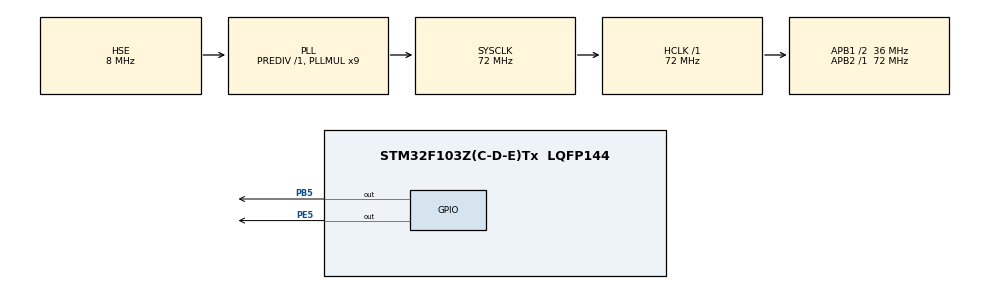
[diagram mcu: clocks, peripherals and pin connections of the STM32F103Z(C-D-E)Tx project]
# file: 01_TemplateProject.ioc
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Mcu.Family=STM32F1
Mcu.Name=STM32F103Z(C-D-E)Tx
Mcu.Package=LQFP144
NVIC.PriorityGroup=NVIC_PRIORITYGROUP_4
OSC_IN.Mode=HSE-External-Oscillator
OSC_IN.Signal=RCC_OSC_IN
OSC_OUT.Mode=HSE-External-Oscillator
OSC_OUT.Signal=RCC_OSC_OUT
PB5.GPIO_PuPd=GPIO_PULLUP
PB5.GPIO_Speed=GPIO_SPEED_FREQ_HIGH
PB5.PinState=GPIO_PIN_SET
PB5.Signal=GPIO_Output
PE5.GPIO_PuPd=GPIO_PULLUP
PE5.GPIO_Speed=GPIO_SPEED_FREQ_HIGH
PE5.PinState=GPIO_PIN_SET
PE5.Signal=GPIO_Output
ProjectManager.HeapSize=0x200
ProjectManager.StackSize=0x400
ProjectManager.TargetToolchain=MDK-ARM V5
RCC.AHBFreq_Value=72000000
RCC.APB1CLKDivider=RCC_HCLK_DIV2
RCC.APB1Freq_Value=36000000
RCC.APB1TimFreq_Value=72000000
RCC.APB2Freq_Value=72000000
RCC.APB2TimFreq_Value=72000000
RCC.HCLKFreq_Value=72000000
RCC.PLLMUL=RCC_PLL_MUL9
RCC.PLLSourceVirtual=RCC_PLLSOURCE_HSE
RCC.SYSCLKFreq_VALUE=72000000
RCC.SYSCLKSource=RCC_SYSCLKSOURCE_PLLCLK
RCC.USBFreq_Value=72000000
VP_SYS_VS_ND.Mode=No_Debug
board=custom

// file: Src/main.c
/* USER CODE BEGIN Header */
/**
  ******************************************************************************
  * @file           : main.c
  * @brief          : Main program body
  ******************************************************************************
  * @attention
  *
  * <h2><center>&copy; Copyright (c) 2019 STMicroelectronics.
  * All rights reserved.</center></h2>
  *
  * This software component is licensed by ST under BSD 3-Clause license,
  * the "License"; You may not use this file except in compliance with the
  * License. You may obtain a copy of the License at:
  *                        opensource.org/licenses/BSD-3-Clause
  *
  ******************************************************************************
  */
/* USER CODE END Header */

#include "main.h"

void SystemClock_Config(void);
static void MX_GPIO_Init(void);

/* USER CODE BEGIN 0 */
void Delay(__IO uint32_t nCount);
void Delay(__IO uint32_t nCount)
{
    while(nCount--) {};
}
/* USER CODE END 0 */

int main(void)
{

  /* MCU Configuration--------------------------------------------------------*/

  /* Reset of all peripherals, Initializes the Flash interface and the Systick. */
  HAL_Init();

  /* Configure the system clock */
  SystemClock_Config();

  /* Initialize all configured peripherals */
  MX_GPIO_Init();

  /* Infinite loop */
  while (1)
  {

    /* USER CODE BEGIN 3 */
      HAL_GPIO_WritePin(GPIOB, GPIO_PIN_5, GPIO_PIN_SET);     //PE5 ��1
      HAL_GPIO_WritePin(GPIOE, GPIO_PIN_5, GPIO_PIN_SET);     //PE5 ��1
      Delay(0x7FFFFF);
      HAL_GPIO_WritePin(GPIOB, GPIO_PIN_5, GPIO_PIN_RESET);   //PE5 ��0
      HAL_GPIO_WritePin(GPIOE, GPIO_PIN_5, GPIO_PIN_RESET);   //PE5 ��0
      Delay(0x7FFFFF);
  }
  /* USER CODE END 3 */
}

void SystemClock_Config(void)
{
  RCC_OscInitTypeDef RCC_OscInitStruct = {0};
  RCC_ClkInitTypeDef RCC_ClkInitStruct = {0};

  /** Initializes the CPU, AHB and APB busses clocks
  */
  RCC_OscInitStruct.OscillatorType = RCC_OSCILLATORTYPE_HSE;
  RCC_OscInitStruct.HSEState = RCC_HSE_ON;
  RCC_OscInitStruct.HSEPredivValue = RCC_HSE_PREDIV_DIV1;
  RCC_OscInitStruct.HSIState = RCC_HSI_ON;
  RCC_OscInitStruct.PLL.PLLState = RCC_PLL_ON;
  RCC_OscInitStruct.PLL.PLLSource = RCC_PLLSOURCE_HSE;
  RCC_OscInitStruct.PLL.PLLMUL = RCC_PLL_MUL9;
  if (HAL_RCC_OscConfig(&RCC_OscInitStruct) != HAL_OK)
  {
    Error_Handler();
  }
  /** Initializes the CPU, AHB and APB busses clocks
  */
  RCC_ClkInitStruct.ClockType = RCC_CLOCKTYPE_HCLK|RCC_CLOCKTYPE_SYSCLK
                              |RCC_CLOCKTYPE_PCLK1|RCC_CLOCKTYPE_PCLK2;
  RCC_ClkInitStruct.SYSCLKSource = RCC_SYSCLKSOURCE_PLLCLK;
  RCC_ClkInitStruct.AHBCLKDivider = RCC_SYSCLK_DIV1;
  RCC_ClkInitStruct.APB1CLKDivider = RCC_HCLK_DIV2;
  RCC_ClkInitStruct.APB2CLKDivider = RCC_HCLK_DIV1;

  if (HAL_RCC_ClockConfig(&RCC_ClkInitStruct, FLASH_LATENCY_2) != HAL_OK)
  {
    Error_Handler();
  }
}

static void MX_GPIO_Init(void)
{
  GPIO_InitTypeDef GPIO_InitStruct = {0};

  /* GPIO Ports Clock Enable */
  __HAL_RCC_GPIOE_CLK_ENABLE();
  __HAL_RCC_GPIOB_CLK_ENABLE();

  /*Configure GPIO pin Output Level */
  HAL_GPIO_WritePin(GPIOE, GPIO_PIN_5, GPIO_PIN_SET);

  /*Configure GPIO pin Output Level */
  HAL_GPIO_WritePin(GPIOB, GPIO_PIN_5, GPIO_PIN_SET);

  /*Configure GPIO pin : PE5 */
  GPIO_InitStruct.Pin = GPIO_PIN_5;
  GPIO_InitStruct.Mode = GPIO_MODE_OUTPUT_PP;
  GPIO_InitStruct.Pull = GPIO_PULLUP;
  GPIO_InitStruct.Speed = GPIO_SPEED_FREQ_HIGH;
  HAL_GPIO_Init(GPIOE, &GPIO_InitStruct);

  /*Configure GPIO pin : PB5 */
  GPIO_InitStruct.Pin = GPIO_PIN_5;
  GPIO_InitStruct.Mode = GPIO_MODE_OUTPUT_PP;
  GPIO_InitStruct.Pull = GPIO_PULLUP;
  GPIO_InitStruct.Speed = GPIO_SPEED_FREQ_HIGH;
  HAL_GPIO_Init(GPIOB, &GPIO_InitStruct);

}

void Error_Handler(void)
{
}

/************************ (C) COPYRIGHT STMicroelectronics *****END OF FILE****/
